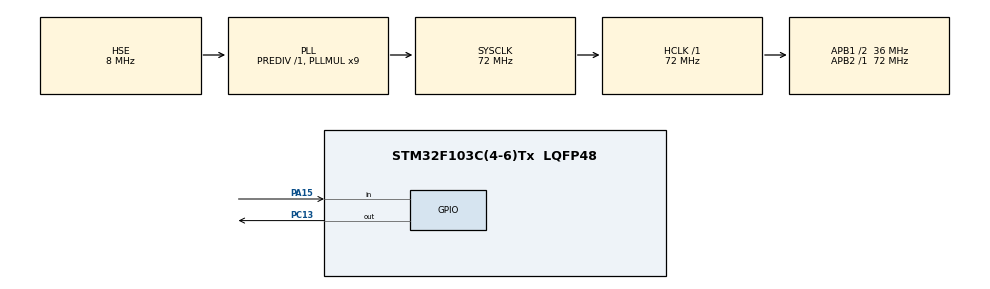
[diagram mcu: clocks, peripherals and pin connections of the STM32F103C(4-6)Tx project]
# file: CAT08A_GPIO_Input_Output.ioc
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Mcu.Family=STM32F1
Mcu.Name=STM32F103C(4-6)Tx
Mcu.Package=LQFP48
NVIC.PriorityGroup=NVIC_PRIORITYGROUP_4
PA13.Mode=Serial_Wire
PA13.Signal=SYS_JTMS-SWDIO
PA14.Mode=Serial_Wire
PA14.Signal=SYS_JTCK-SWCLK
PA15.GPIO_PuPd=GPIO_PULLUP
PA15.Signal=GPIO_Input
PC13-TAMPER-RTC.Signal=GPIO_Output
PD0-OSC_IN.Mode=HSE-External-Oscillator
PD0-OSC_IN.Signal=RCC_OSC_IN
PD1-OSC_OUT.Mode=HSE-External-Oscillator
PD1-OSC_OUT.Signal=RCC_OSC_OUT
ProjectManager.HeapSize=0x200
ProjectManager.StackSize=0x400
ProjectManager.TargetToolchain=STM32CubeIDE
RCC.AHBFreq_Value=72000000
RCC.APB1CLKDivider=RCC_HCLK_DIV2
RCC.APB1Freq_Value=36000000
RCC.APB1TimFreq_Value=72000000
RCC.APB2Freq_Value=72000000
RCC.APB2TimFreq_Value=72000000
RCC.HCLKFreq_Value=72000000
RCC.PLLMUL=RCC_PLL_MUL9
RCC.PLLSourceVirtual=RCC_PLLSOURCE_HSE
RCC.SYSCLKFreq_VALUE=72000000
RCC.SYSCLKSource=RCC_SYSCLKSOURCE_PLLCLK
RCC.USBFreq_Value=72000000
board=custom

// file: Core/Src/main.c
/* USER CODE BEGIN Header */
/**
  ******************************************************************************
  * @file           : main.c
  * @brief          : CAT 8 - Task 8A : GPIO input/output - LED follows the push-button
  *                    Board: STM32 Blue Pill (STM32F103C6T6), LED PC13 (active-low), button PA15 (pull-up)
  ******************************************************************************
  * @attention
  *
  * Copyright (c) 2026 STMicroelectronics.
  * All rights reserved.
  *
  * This software is licensed under terms that can be found in the LICENSE file
  * in the root directory of this software component.
  * If no LICENSE file comes with this software, it is provided AS-IS.
  *
  ******************************************************************************
  */
/* USER CODE END Header */
#include "main.h"

/* USER CODE BEGIN PD */
/* Blue Pill on-board LED: PC13, ACTIVE-LOW (LED glows when the pin is 0) */
#define LED_PORT        GPIOC
#define LED_PIN         GPIO_PIN_13
#define LED_ON_LEVEL    GPIO_PIN_RESET
#define LED_OFF_LEVEL   GPIO_PIN_SET

/* Push-button: PA15 to GND, internal pull-up -> reads 0 while pressed.
 * PA15 is JTDI after reset, so Debug = "Serial Wire" in CubeMX frees it. */
#define BTN_PORT        GPIOA
#define BTN_PIN         GPIO_PIN_15
/* USER CODE END PD */

void SystemClock_Config(void);
static void MX_GPIO_Init(void);

/* USER CODE BEGIN 0 */
static inline uint8_t button_raw_pressed(void)
{
  return (HAL_GPIO_ReadPin(BTN_PORT, BTN_PIN) == GPIO_PIN_RESET);
}

static inline void led_write(uint8_t on)
{
  HAL_GPIO_WritePin(LED_PORT, LED_PIN, on ? LED_ON_LEVEL : LED_OFF_LEVEL);
}
/* USER CODE END 0 */

int main(void)
{

  /* MCU Configuration--------------------------------------------------------*/

  /* Reset of all peripherals, Initializes the Flash interface and the Systick. */
  HAL_Init();

  /* Configure the system clock */
  SystemClock_Config();

  /* Initialize all configured peripherals */
  MX_GPIO_Init();
  /* USER CODE BEGIN 2 */
  /* Start with the LED OFF */
  led_write(0);
  /* USER CODE END 2 */

  /* Infinite loop */
  while (1)
  {

    /* USER CODE BEGIN 3 */
    /* Task 8A: the LED simply follows the switch.
     * pressed (PA15 = 0)  -> LED ON  (PC13 = 0)
     * released (PA15 = 1) -> LED OFF (PC13 = 1) */
    led_write(button_raw_pressed());
  }
  /* USER CODE END 3 */
}

void SystemClock_Config(void)
{
  RCC_OscInitTypeDef RCC_OscInitStruct = {0};
  RCC_ClkInitTypeDef RCC_ClkInitStruct = {0};

  /** Initializes the RCC Oscillators according to the specified parameters
  * in the RCC_OscInitTypeDef structure.
  */
  RCC_OscInitStruct.OscillatorType = RCC_OSCILLATORTYPE_HSE;
  RCC_OscInitStruct.HSEState = RCC_HSE_ON;
  RCC_OscInitStruct.HSEPredivValue = RCC_HSE_PREDIV_DIV1;
  RCC_OscInitStruct.HSIState = RCC_HSI_ON;
  RCC_OscInitStruct.PLL.PLLState = RCC_PLL_ON;
  RCC_OscInitStruct.PLL.PLLSource = RCC_PLLSOURCE_HSE;
  RCC_OscInitStruct.PLL.PLLMUL = RCC_PLL_MUL9;
  if (HAL_RCC_OscConfig(&RCC_OscInitStruct) != HAL_OK)
  {
    Error_Handler();
  }

  /** Initializes the CPU, AHB and APB buses clocks
  */
  RCC_ClkInitStruct.ClockType = RCC_CLOCKTYPE_HCLK|RCC_CLOCKTYPE_SYSCLK
                              |RCC_CLOCKTYPE_PCLK1|RCC_CLOCKTYPE_PCLK2;
  RCC_ClkInitStruct.SYSCLKSource = RCC_SYSCLKSOURCE_PLLCLK;
  RCC_ClkInitStruct.AHBCLKDivider = RCC_SYSCLK_DIV1;
  RCC_ClkInitStruct.APB1CLKDivider = RCC_HCLK_DIV2;
  RCC_ClkInitStruct.APB2CLKDivider = RCC_HCLK_DIV1;

  if (HAL_RCC_ClockConfig(&RCC_ClkInitStruct, FLASH_LATENCY_2) != HAL_OK)
  {
    Error_Handler();
  }
}

static void MX_GPIO_Init(void)
{
  GPIO_InitTypeDef GPIO_InitStruct = {0};

  /* GPIO Ports Clock Enable */
  __HAL_RCC_GPIOC_CLK_ENABLE();
  __HAL_RCC_GPIOD_CLK_ENABLE();
  __HAL_RCC_GPIOA_CLK_ENABLE();

  /*Configure GPIO pin Output Level */
  HAL_GPIO_WritePin(GPIOC, GPIO_PIN_13, GPIO_PIN_RESET);

  /*Configure GPIO pin : PC13 */
  GPIO_InitStruct.Pin = GPIO_PIN_13;
  GPIO_InitStruct.Mode = GPIO_MODE_OUTPUT_PP;
  GPIO_InitStruct.Pull = GPIO_NOPULL;
  GPIO_InitStruct.Speed = GPIO_SPEED_FREQ_LOW;
  HAL_GPIO_Init(GPIOC, &GPIO_InitStruct);

  /*Configure GPIO pin : PA15 */
  GPIO_InitStruct.Pin = GPIO_PIN_15;
  GPIO_InitStruct.Mode = GPIO_MODE_INPUT;
  GPIO_InitStruct.Pull = GPIO_PULLUP;
  HAL_GPIO_Init(GPIOA, &GPIO_InitStruct);

}

void Error_Handler(void)
{
  __disable_irq();
  while (1)
  {
  }
}
